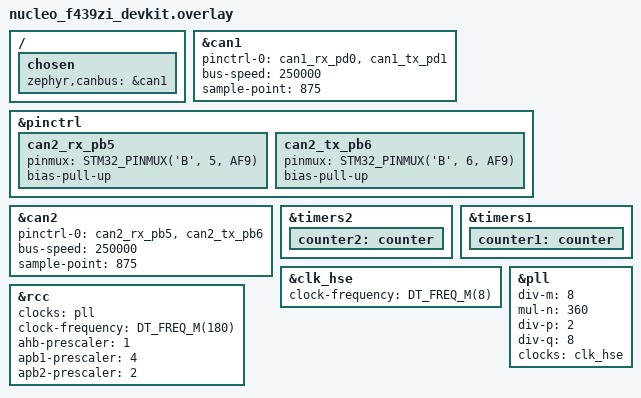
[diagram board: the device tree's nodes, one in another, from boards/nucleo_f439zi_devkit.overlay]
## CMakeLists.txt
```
cmake_minimum_required(VERSION 3.20.0)

find_package(Zephyr REQUIRED HINTS $ENV{ZEPHYR_BASE})
project(main_pipeline)

target_sources(app PRIVATE
    src/main.c
    src/timestamp.c
    src/can_handler.c
    src/button.c
    src/stats.c
)
```

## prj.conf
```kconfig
CONFIG_CAN=y
CONFIG_CAN_STATS=n
CONFIG_GPIO=y
CONFIG_COUNTER=y
# Log settings help with debugging if the bus goes off
CONFIG_LOG=y
CONFIG_LOG_MODE_DEFERRED=y
#CONFIG_CAN_LOG_LEVEL_DBG=y
#CONFIG_CAN_LOG_LEVEL_WRN=y

# Give CAN interrupts higher priority
CONFIG_CAN_INIT_PRIORITY=41

# Increase system clock if not already at max
#           CONFIG_SYS_CLOCK_HW_CYCLES_PER_SEC=168000000
#CONFIG_SYSTEM_CLOCK_HW_CYCLES_PER_SEC_RUNTIME_UPDATE=y

# Optimize kernel
CONFIG_SCHED_SCALABLE=y
CONFIG_TIMESLICING=n

CONFIG_CLOCK_CONTROL=y


# Need to check below settings for logging and shell, as they can cause performance issues
#CONFIG_LOG_BACKEND_UART_OUTPUT_DICTIONARY_HEX=n
#CONFIG_SHELL_VT100_COLORS=n
```

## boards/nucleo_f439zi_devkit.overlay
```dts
/ {
    chosen {
        zephyr,canbus = &can1;
    };
};

/* CAN1 — PD0/PD1 on CN9 */
&can1 {
    status = "okay";
    pinctrl-0 = <&can1_rx_pd0 &can1_tx_pd1>;
    pinctrl-names = "default";
    bus-speed = <250000>;
    sample-point = <875>;
};

/* CAN2 — PB5 (RX) on CN7 pin14, PB6 (TX) on CN10 pin13 */
&pinctrl {
    can2_rx_pb5: can2_rx_pb5 {
        pinmux = <STM32_PINMUX('B', 5, AF9)>;
        bias-pull-up;
    };
    can2_tx_pb6: can2_tx_pb6 {
        pinmux = <STM32_PINMUX('B', 6, AF9)>;
        bias-pull-up;
    };
};

&can2 {
    status = "okay";
    pinctrl-0 = <&can2_rx_pb5 &can2_tx_pb6>;
    pinctrl-names = "default";
    bus-speed = <250000>;
    sample-point = <875>;
};

&timers2 {
    status = "okay";
    counter2: counter {
        status = "okay";
    };
};

&timers1 {
    status = "okay";
    counter1: counter {
        status = "okay";
    };
};

&clk_hse {
    clock-frequency = <DT_FREQ_M(8)>;
    status = "okay";
};

&pll {
    /* Formula: (HSE / M) * N / P = Frequency */
    /* (8MHz / 8) * 360 / 2 = 180MHz */
    div-m = <8>;
    mul-n = <360>;
    div-p = <2>;
    div-q = <8>;
    clocks = <&clk_hse>;
    status = "okay";
};

&rcc {
    clocks = <&pll>;
    clock-frequency = <DT_FREQ_M(180)>;
    ahb-prescaler = <1>;
    apb1-prescaler = <4>; /* Max 45MHz for APB1 */
    apb2-prescaler = <2>; /* Max 90MHz for APB2 */
};
```

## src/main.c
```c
#include <zephyr/kernel.h>
#include "timestamp.h"
#include "can_handler.h"
#include "button.h"

#define SLEEP_TIME_MS 100

int main(void){
    timestamp_init();
    can_handler_init();
    button_init();

    printk("==========================================\n");
    printk("    CAN Latency Tester - Initialized     \n");
    printk("==========================================\n");
    printk("  Send Interval: %d ms\n", SLEEP_TIME_MS);
    printk("==========================================\n");

    while(1){
        if(can_send_enabled){
            uint32_t ts = get_hw_timestamp_us();
            int ret = can_send_frame(ts,tx_sequence_num);
            if(ret != 0){
                printk("[TX] Send failed [%d] seq=%u\n", ret, tx_sequence_num);
            } else {
                printk("[TX] Seq=%u @ %u us\n", tx_sequence_num, ts);
            }
            tx_sequence_num++;
        }
        k_msleep(SLEEP_TIME_MS);
    }
    return 0;
}
```

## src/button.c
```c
#include "button.h"
#include "can_handler.h"
#include "stats.h"
#include <zephyr/kernel.h>
#include <zephyr/drivers/gpio.h>

#define SW0_NODE DT_ALIAS(sw0)
#define BUTTON_DEBOUNCE_MS 500

static const struct gpio_dt_spec button = GPIO_DT_SPEC_GET(SW0_NODE, gpios);
static struct gpio_callback button_cb_data;

static void button_pressed(const struct device *dev, struct gpio_callback *cb, uint32_t pins)
{
    static int64_t last_press_time = 0;
    int64_t now = k_uptime_get();

    if (now - last_press_time < BUTTON_DEBOUNCE_MS) {
        return;
    }
    last_press_time = now;

    can_send_enabled = !can_send_enabled;

    if (can_send_enabled){
        printk("[%u ms] *** CAN SENDING RESUMED ***\n", k_uptime_get_32());
    } else {
        printk("[%u ms] *** CAN SENDING PAUSED ***\n", k_uptime_get_32());
        stats_print(tx_sequence_num);
    }
}

int button_init(void)
{
    int ret;

    if (!gpio_is_ready_dt(&button)){
        printk("Error: button device not ready\n");
        return -ENODEV;
    }

    ret = gpio_pin_configure_dt(&button, GPIO_INPUT);
    if (ret != 0){
        printk("Error %d: failed to configure button pin\n", ret);
        return ret;
    }

    ret = gpio_pin_interrupt_configure_dt(&button, GPIO_INT_EDGE_TO_ACTIVE);
    if(ret != 0){
        printk("Error %d: failed to configure button interrupt\n", ret);
        return ret;
    }

    gpio_init_callback(&button_cb_data, button_pressed, BIT(button.pin));
    gpio_add_callback(button.port, &button_cb_data);
    return 0;
}
```

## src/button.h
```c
#ifndef BUTTON_H
#define BUTTON_H

int button_init(void);

#endif
```

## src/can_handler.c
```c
#include "can_handler.h"
#include "timestamp.h"
#include "stats.h"
#include <zephyr/kernel.h>
#include <string.h>
#include <zephyr/logging/log.h>
LOG_MODULE_REGISTER(can_handler, LOG_LEVEL_INF);

const struct device *const can1_dev = DEVICE_DT_GET(DT_NODELABEL(can1));
const struct device *const can2_dev = DEVICE_DT_GET(DT_NODELABEL(can2));

volatile bool can_send_enabled = false;
uint32_t tx_sequence_num = 0;

static void can_rx_callback(const struct device *dev, struct can_frame *frame, void *user_data)
{
    uint32_t rx_timestamp_us = get_hw_timestamp_us();
    uint32_t tx_timestamp_us, latency_us, rx_seq_num;

    memcpy(&tx_timestamp_us, frame->data, sizeof(uint32_t));
    memcpy(&rx_seq_num, &frame->data[4], sizeof(uint32_t));

    if (rx_timestamp_us >= tx_timestamp_us) {
        latency_us = rx_timestamp_us - tx_timestamp_us;
    } else {
        latency_us = rx_timestamp_us + (get_timer_max_us() - tx_timestamp_us);
    }

    uint32_t jitter_us = stats_record(latency_us, rx_seq_num);

    LOG_INF("CSV,%u,%u,%u,%u,%u", rx_seq_num, tx_timestamp_us, rx_timestamp_us, latency_us, jitter_us);
    // printk("CSV,%u,%u,%u,%u,%u\n", rx_seq_num, tx_timestamp_us, rx_timestamp_us, latency_us, jitter_us);
    // printk("[RX] Seq=%u, Latency=%u us, Jitter=%u us\n", rx_seq_num, latency_us, jitter_us);
}

int can_handler_init(void)
{
    int ret;

    if(!device_is_ready(can1_dev) || !device_is_ready(can2_dev)) {
        printk("CAN devices not ready\n");
        return -ENODEV;
    }

    // for the testing use the CAN_NORMAL mode, which is the default. In this mode, the CAN controller will automatically handle ACKs and retransmissions.
    // This allows us to focus on measuring the latency without worrying about packet loss or retries.
    can_set_mode(can1_dev, CAN_MODE_NORMAL);
    can_start(can1_dev);

    ret = can_set_mode(can2_dev, CAN_MODE_NORMAL);
    if (ret != 0) {
        printk("Error setting CAN2 mode [%d]\n", ret);
        return ret;
    }

    ret = can_start(can2_dev);
    if (ret != 0) {
        printk("Error starting CAN2 [%d]\n", ret);
        return ret;
    }

    struct can_filter filter = {
        .flags = 0,
        .id = 0x123,
        .mask = CAN_STD_ID_MASK
    };

    int filter_id = can_add_rx_filter(can2_dev, can_rx_callback, NULL, &filter);
    if (filter_id < 0) {
        printk("Error adding CAN2 RX filter [%d]\n", filter_id);
        return filter_id;
    }

    return 0;
}

int can_send_frame(uint32_t timestamp_us, uint32_t seq_num)
{
    struct can_frame frame = {
        .id = 0x123,
        .flags = 0,
        .dlc = 8,
        .data = {0}
    };

    memcpy(frame.data, &timestamp_us, sizeof(uint32_t));
    memcpy(&frame.data[4], &seq_num, sizeof(uint32_t));

    return can_send(can1_dev, &frame, K_MSEC(100), NULL, NULL);
}
```

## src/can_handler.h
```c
#ifndef CAN_HANDLER_H
#define CAN_HANDLER_H

#include <zephyr/drivers/can.h>
#include <stdbool.h>
#include <stdint.h>

extern const struct device *const can1_dev;
extern const struct device *const can2_dev;
extern volatile bool can_send_enabled;
extern uint32_t tx_sequence_num;

int can_handler_init(void);
int can_send_frame(uint32_t timestamp_us, uint32_t seq_num);

#endif
```

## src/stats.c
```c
#include "stats.h"
#include <zephyr/kernel.h>
#include <limits.h>

struct latency_stats stats = {
    .min_us = UINT32_MAX,
    .max_us = 0,
    .total_us = 0,
    .count = 0,
    .prev_latency_us = 0,
    .total_jitter_us = 0,
    .max_jitter_us = 0,
    .lost_packets = 0,
    .last_rx_seq = 0
};

void stats_reset(void){
    stats.min_us = UINT32_MAX;
    stats.max_us = 0;
    stats.total_us = 0;
    stats.count = 0;
    stats.prev_latency_us = 0;
    stats.total_jitter_us = 0;
    stats.max_jitter_us = 0;
    stats.lost_packets = 0;
    stats.last_rx_seq = 0;
};

uint32_t stats_record(uint32_t latency_us, uint32_t rx_seq_num) {
    // Packet loss detection
    if (stats.count > 0) {
        uint32_t expected_seq = stats.last_rx_seq + 1;
        if (rx_seq_num != expected_seq) {
            uint32_t lost = rx_seq_num - expected_seq;
            stats.lost_packets += lost;
            printk("Packet loss detected: expected seq %u, got %u, lost %u\n", expected_seq, rx_seq_num, lost);
        }
    }
    stats.last_rx_seq = rx_seq_num;

    // Jitter calculation
    uint32_t jitter_us = 0;
    if (stats.count > 0) {
        jitter_us = (latency_us > stats.prev_latency_us) ? (latency_us - stats.prev_latency_us) : (stats.prev_latency_us - latency_us);
        stats.total_jitter_us += jitter_us;
        if (jitter_us > stats.max_jitter_us) {
            stats.max_jitter_us = jitter_us;
        }
    }
    stats.prev_latency_us = latency_us;

    // Min/Max/Total
    stats.count++;
    stats.total_us += latency_us;
    if (latency_us < stats.min_us) stats.min_us = latency_us;
    if (latency_us > stats.max_us) stats.max_us = latency_us;
    return jitter_us;
}

void stats_print(uint32_t tx_count)
{
    if (stats.count == 0) return;

    uint32_t avg_latency = stats.total_us / stats.count;
    uint32_t avg_jitter = (stats.count > 1)
                          ? stats.total_jitter_us / (stats.count - 1) : 0;

    printk("\n==========================================\n");
    printk("       LATENCY STATISTICS SUMMARY        \n");
    printk("==========================================\n");
    printk("Messages Sent:     %u\n", tx_count);
    printk("Messages Received: %u\n", stats.count);
    printk("Packets Lost:      %u\n", stats.lost_packets);
    printk("Packet Loss Rate:  %u.%02u%%\n",
           (stats.lost_packets * 100) / tx_count,
           ((stats.lost_packets * 10000) / tx_count) % 100);
    printk("------------------------------------------\n");
    printk("Latency (us):\n");
    printk("  Min:      %u\n", stats.min_us);
    printk("  Max:      %u\n", stats.max_us);
    printk("  Average:  %u\n", avg_latency);
    printk("  Range:    %u\n", stats.max_us - stats.min_us);
    printk("------------------------------------------\n");
    printk("Jitter (us):\n");
    printk("  Max:      %u\n", stats.max_jitter_us);
    printk("  Average:  %u\n", avg_jitter);
    printk("==========================================\n\n");
}
```

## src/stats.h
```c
#ifndef STATS_H
#define STATS_H

#include <stdint.h>

struct latency_stats {
    uint32_t min_us;
    uint32_t max_us;
    uint32_t total_us;
    uint32_t count;
    uint32_t prev_latency_us;
    uint32_t total_jitter_us;
    uint32_t max_jitter_us;
    uint32_t lost_packets;
    uint32_t last_rx_seq;
};

extern struct latency_stats stats;

void stats_reset(void);
uint32_t stats_record(uint32_t latency_us, uint32_t rx_seq_num);
void stats_print(uint32_t tx_count);

#endif
```

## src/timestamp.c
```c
#include "timestamp.h"
#include <zephyr/drivers/counter.h>
#include <zephyr/devicetree.h>

#define TIMER_NODE DT_NODELABEL(counter2)

const struct device *counter_dev = DEVICE_DT_GET(TIMER_NODE);

void timestamp_init(void)
{
    struct counter_top_cfg top_cfg = {
        .callback = NULL,
        .ticks = counter_get_max_top_value(counter_dev),
        .user_data = NULL,
        .flags = 0,
    };

    counter_set_top_value(counter_dev, &top_cfg);
    counter_start(counter_dev);
}

uint32_t get_hw_timestamp_us(void)
{
    uint32_t ticks;
    counter_get_value(counter_dev, &ticks);
    return counter_ticks_to_us(counter_dev, ticks);
}

uint32_t get_timer_max_us(void)
{
    uint32_t max_ticks = counter_get_max_top_value(counter_dev);
    return counter_ticks_to_us(counter_dev, max_ticks);
}
```

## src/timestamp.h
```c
#ifndef TIMESTAMP_H
#define TIMESTAMP_H

#include <zephyr/device.h>
#include <stdint.h>

extern const struct device *counter_dev; 

void timestamp_init(void);
uint32_t get_hw_timestamp_us(void);
uint32_t get_timer_max_us(void);

#endif
```
